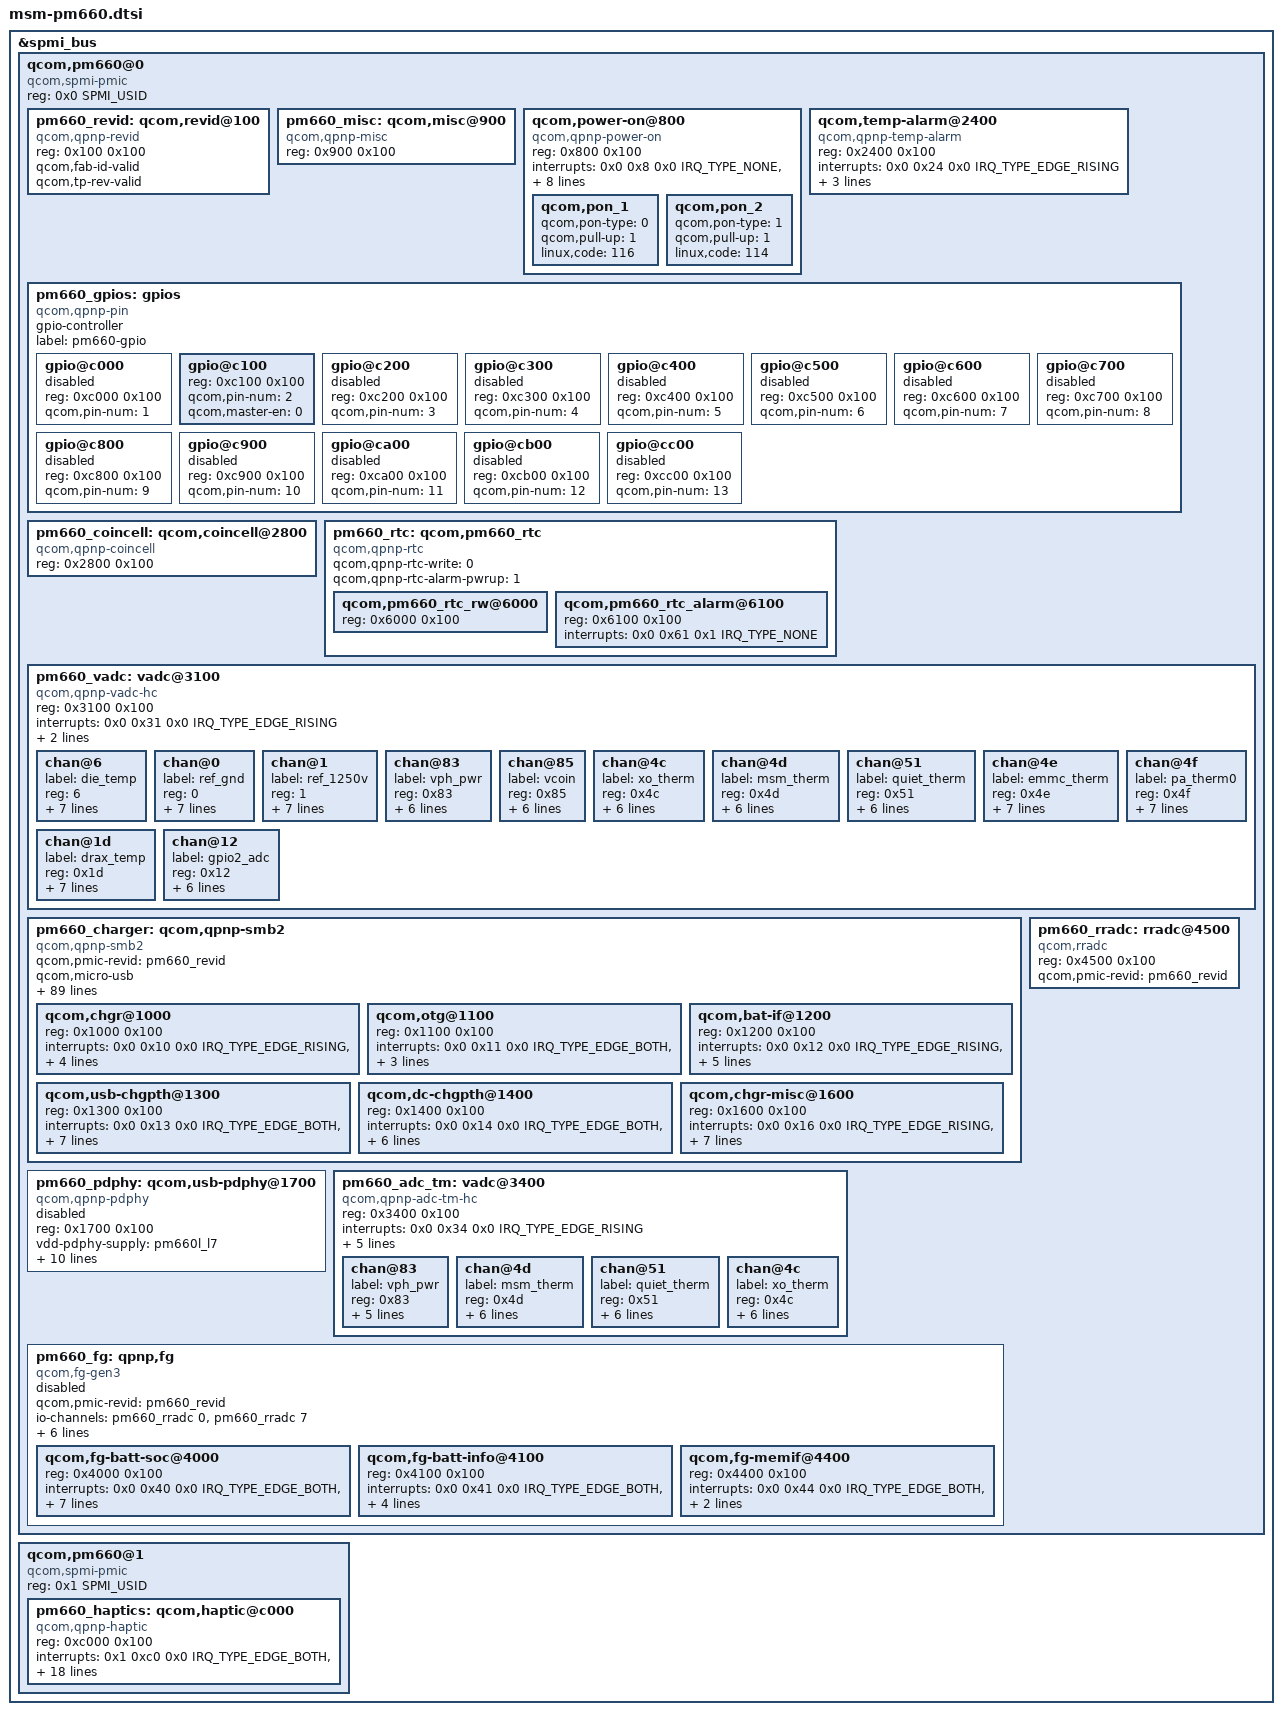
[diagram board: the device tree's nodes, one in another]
/* Copyright (c) 2016-2017, The Linux Foundation. All rights reserved.
 *
 * This program is free software; you can redistribute it and/or modify
 * it under the terms of the GNU General Public License version 2 and
 * only version 2 as published by the Free Software Foundation.
 *
 * This program is distributed in the hope that it will be useful,
 * but WITHOUT ANY WARRANTY; without even the implied warranty of
 * MERCHANTABILITY or FITNESS FOR A PARTICULAR PURPOSE.  See the
 * GNU General Public License for more details.
 */

#include <dt-bindings/spmi/spmi.h>
#include <dt-bindings/interrupt-controller/irq.h>

&spmi_bus {
	qcom,pm660@0 {
		compatible ="qcom,spmi-pmic";
		reg = <0x0 SPMI_USID>;
		#address-cells = <2>;
		#size-cells = <0>;

		pm660_revid: qcom,revid@100 {
			compatible = "qcom,qpnp-revid";
			reg = <0x100 0x100>;
			qcom,fab-id-valid;
			qcom,tp-rev-valid;
		};

		pm660_misc: qcom,misc@900 {
			compatible = "qcom,qpnp-misc";
			reg = <0x900 0x100>;
		};

		qcom,power-on@800 {
			compatible = "qcom,qpnp-power-on";
			reg = <0x800 0x100>;
			interrupts = <0x0 0x8 0x0 IRQ_TYPE_NONE>,
				     <0x0 0x8 0x1 IRQ_TYPE_NONE>,
				     <0x0 0x8 0x4 IRQ_TYPE_NONE>,
				     <0x0 0x8 0x5 IRQ_TYPE_NONE>;
			interrupt-names = "kpdpwr", "resin",
					"resin-bark", "kpdpwr-resin-bark";
			qcom,pon-dbc-delay = <15625>;
			qcom,kpdpwr-sw-debounce;
			qcom,system-reset;
			qcom,store-hard-reset-reason;
			//#ifdef VENDOR_EDIT //yixue.ge@bsp.drv add for use hard reset reason
			qcom,clear-warm-reset;
			//#endif

			qcom,pon_1 {
				qcom,pon-type = <0>;
				qcom,pull-up = <1>;
				linux,code = <116>;
			};

			qcom,pon_2 {
				qcom,pon-type = <1>;
				qcom,pull-up = <1>;
				linux,code = <114>;
			};
		};

		qcom,temp-alarm@2400 {
			compatible = "qcom,qpnp-temp-alarm";
			reg = <0x2400 0x100>;
			interrupts = <0x0 0x24 0x0 IRQ_TYPE_EDGE_RISING>;
			label = "pm660_tz";
			qcom,channel-num = <6>;
			qcom,temp_alarm-vadc = <&pm660_vadc>;
		};

		pm660_gpios: gpios {
			compatible = "qcom,qpnp-pin";
			gpio-controller;
			#gpio-cells = <2>;
			#address-cells = <1>;
			#size-cells = <1>;
			label = "pm660-gpio";

			gpio@c000 {
				reg = <0xc000 0x100>;
				qcom,pin-num = <1>;
				status = "disabled";
			};

			gpio@c100 {
				reg = <0xc100 0x100>;
				qcom,pin-num = <2>;
//#ifdef VENDOR_EDIT /* Jianchao.Shi@BSP.CHG.Basic, 2017/01/23, sjc Modify for charging */
				//status = "disabled";
				status = "ok";
				//qcom,mode = <3>; //ANA_PASS_THRU
				qcom,master-en = <0>; //disable GPIO
//#endif
			};

			gpio@c200 {
				reg = <0xc200 0x100>;
				qcom,pin-num = <3>;
				status = "disabled";
			};

			gpio@c300 {
				reg = <0xc300 0x100>;
				qcom,pin-num = <4>;
				status = "disabled";
			};

			gpio@c400 {
				reg = <0xc400 0x100>;
				qcom,pin-num = <5>;
				status = "disabled";
			};

			gpio@c500 {
				reg = <0xc500 0x100>;
				qcom,pin-num = <6>;
				status = "disabled";
			};

			gpio@c600 {
				reg = <0xc600 0x100>;
				qcom,pin-num = <7>;
				status = "disabled";
			};

			gpio@c700 {
				reg = <0xc700 0x100>;
				qcom,pin-num = <8>;
				status = "disabled";
			};

			gpio@c800 {
				reg = <0xc800 0x100>;
				qcom,pin-num = <9>;
				status = "disabled";
			};

			gpio@c900 {
				reg = <0xc900 0x100>;
				qcom,pin-num = <10>;
				status = "disabled";
			};

			gpio@ca00 {
				reg = <0xca00 0x100>;
				qcom,pin-num = <11>;
				status = "disabled";
			};

			gpio@cb00 {
				reg = <0xcb00 0x100>;
				qcom,pin-num = <12>;
				status = "disabled";
			};

			gpio@cc00 {
				reg = <0xcc00 0x100>;
				qcom,pin-num = <13>;
				status = "disabled";
			};
		};

		pm660_coincell: qcom,coincell@2800 {
			compatible = "qcom,qpnp-coincell";
			reg = <0x2800 0x100>;
		};

		pm660_rtc: qcom,pm660_rtc {
			compatible = "qcom,qpnp-rtc";
			#address-cells = <1>;
			#size-cells = <1>;
			qcom,qpnp-rtc-write = <0>;
		   //#ifndef VENDOR_EDIT
           /*Tong.han@BSP.group.TP Modified for rtc restart phone. 2014-08-12*/
           //  qcom,qpnp-rtc-alarm-pwrup = <0>;  
	       //#else
 		     qcom,qpnp-rtc-alarm-pwrup = <1>;
	       //#endif

			qcom,pm660_rtc_rw@6000 {
				reg = <0x6000 0x100>;
			};
			qcom,pm660_rtc_alarm@6100 {
				reg = <0x6100 0x100>;
				interrupts = <0x0 0x61 0x1 IRQ_TYPE_NONE>;
			};
		};

		pm660_vadc: vadc@3100 {
			compatible = "qcom,qpnp-vadc-hc";
			reg = <0x3100 0x100>;
			#address-cells = <1>;
			#size-cells = <0>;
			interrupts = <0x0 0x31 0x0 IRQ_TYPE_EDGE_RISING>;
			interrupt-names = "eoc-int-en-set";
			qcom,adc-bit-resolution = <15>;
			qcom,adc-vdd-reference = <1875>;

			chan@6 {
				label = "die_temp";
				reg = <6>;
				qcom,decimation = <2>;
				qcom,pre-div-channel-scaling = <0>;
				qcom,calibration-type = "absolute";
				qcom,scale-function = <3>;
				qcom,hw-settle-time = <0>;
				qcom,fast-avg-setup = <0>;
				qcom,cal-val = <0>;
			};

			chan@0 {
				label = "ref_gnd";
				reg = <0>;
				qcom,decimation = <2>;
				qcom,pre-div-channel-scaling = <0>;
				qcom,calibration-type = "absolute";
				qcom,scale-function = <0>;
				qcom,hw-settle-time = <0>;
				qcom,fast-avg-setup = <0>;
				qcom,cal-val = <0>;
			};

			chan@1 {
				label = "ref_1250v";
				reg = <1>;
				qcom,decimation = <2>;
				qcom,pre-div-channel-scaling = <0>;
				qcom,calibration-type = "absolute";
				qcom,scale-function = <0>;
				qcom,hw-settle-time = <0>;
				qcom,fast-avg-setup = <0>;
				qcom,cal-val = <0>;
			};

			chan@83 {
				label = "vph_pwr";
				reg = <0x83>;
				qcom,decimation = <2>;
				qcom,pre-div-channel-scaling = <1>;
				qcom,calibration-type = "absolute";
				qcom,scale-function = <0>;
				qcom,hw-settle-time = <0>;
				qcom,fast-avg-setup = <0>;
			};

			chan@85 {
				label = "vcoin";
				reg = <0x85>;
				qcom,decimation = <2>;
				qcom,pre-div-channel-scaling = <1>;
				qcom,calibration-type = "absolute";
				qcom,scale-function = <0>;
				qcom,hw-settle-time = <0>;
				qcom,fast-avg-setup = <0>;
			};

			chan@4c {
				label = "xo_therm";
				reg = <0x4c>;
				qcom,decimation = <2>;
				qcom,pre-div-channel-scaling = <0>;
				qcom,calibration-type = "ratiometric";
				qcom,scale-function = <4>;
				qcom,hw-settle-time = <2>;
				qcom,fast-avg-setup = <0>;
			};

			chan@4d {
				label = "msm_therm";
				reg = <0x4d>;
				qcom,decimation = <2>;
				qcom,pre-div-channel-scaling = <0>;
				qcom,calibration-type = "ratiometric";
				qcom,scale-function = <2>;
				qcom,hw-settle-time = <2>;
				qcom,fast-avg-setup = <0>;
			};

			chan@51 {
				label = "quiet_therm";
				reg = <0x51>;
				qcom,decimation = <2>;
				qcom,pre-div-channel-scaling = <0>;
				qcom,calibration-type = "ratiometric";
				qcom,scale-function = <2>;
				qcom,hw-settle-time = <2>;
				qcom,fast-avg-setup = <0>;
			};

			chan@4e {
				label = "emmc_therm";
				reg = <0x4e>;
				qcom,decimation = <2>;
				qcom,pre-div-channel-scaling = <0>;
				qcom,calibration-type = "ratiometric";
				qcom,scale-function = <2>;
				qcom,hw-settle-time = <2>;
				qcom,fast-avg-setup = <0>;
				qcom,vadc-thermal-node;
			};

			chan@4f {
				label = "pa_therm0";
				reg = <0x4f>;
				qcom,decimation = <2>;
				qcom,pre-div-channel-scaling = <0>;
				qcom,calibration-type = "ratiometric";
				qcom,scale-function = <2>;
				qcom,hw-settle-time = <2>;
				qcom,fast-avg-setup = <0>;
				qcom,vadc-thermal-node;
			};

			chan@1d {
				label = "drax_temp";
				reg = <0x1d>;
				qcom,decimation = <2>;
				qcom,pre-div-channel-scaling = <0>;
				qcom,calibration-type = "absolute";
				qcom,scale-function = <3>;
				qcom,hw-settle-time = <0>;
				qcom,fast-avg-setup = <0>;
				qcom,cal-val = <0>;
			};

//#ifdef VENDOR_EDIT /* Jianchao.Shi@BSP.CHG.Basic, 2017/01/23, sjc Add for charging */
			chan@12 {
				label = "gpio2_adc";
				reg = <0x12>; //channel for GPIO2
				qcom,decimation = <2>;
				qcom,pre-div-channel-scaling = <0>; //1:1 scaling
				qcom,calibration-type = "absolute";
				qcom,scale-function = <0>;
				qcom,hw-settle-time = <2>;
				qcom,fast-avg-setup = <0>;
			};
//#endif
		};

		pm660_charger: qcom,qpnp-smb2 {
			compatible = "qcom,qpnp-smb2";
			#address-cells = <1>;
			#size-cells = <1>;

			qcom,pmic-revid = <&pm660_revid>;
//#ifdef VENDOR_EDIT /* Jianchao.Shi@BSP.CHG.Basic, 2017/01/18, sjc Add for charging */
			qcom,micro-usb;
//#endif

			io-channels = <&pm660_rradc 8>,
				      <&pm660_rradc 10>,
				      <&pm660_rradc 3>,
				      <&pm660_rradc 4>;
			io-channel-names = "charger_temp",
					   "charger_temp_max",
					   "usbin_i",
					   "usbin_v";

//#ifdef VENDOR_EDIT /* Jianchao.Shi@BSP.CHG.Basic, 2017/01/20, sjc Delete for charging */
			//qcom,wipower-max-uw = <5000000>;
//#endif
			dpdm-supply = <&qusb_phy0>;
//#ifdef VENDOR_EDIT /* Jianchao.Shi@BSP.CHG.Basic, 2017/05/12, sjc Modify for BOB noise*/
			pm660l_bob-supply = <&pm660l_bob>;
//#endif

			qcom,thermal-mitigation
					= <3000000 2500000 2000000 1500000
						1000000 500000>;

//#ifdef VENDOR_EDIT /* Jianchao.Shi@BSP.CHG.Basic, 2016/12/26, sjc Add for charging */
			//for smb2:
			qcom,usb-icl-ua = <2000000>;
			qcom,fcc-max-ua = <2000000>;
			//qcom,fv-max-uv = <4373000>;
			qcom,hvdcp-disable;
			qcom,pm660chg-vadc = <&pm660_vadc>;
			//qcom,otg-cl-ua = <2000000>;

			//for oppo chg framework:
			qcom,input_current_charger_ma = <2000>;
			qcom,input_current_usb_ma = <500>;
			qcom,input_current_led_ma = <1200>;
			qcom,input_current_led_ma_forcmcc = <500>;
			qcom,input_current_camera_ma = <1200>;
			//qcom,input_current_led_ma_overtemp = <900>;
			qcom,overtemp_bat_decidegc = <350>;
			qcom,iterm-disabled = <0>;
			qcom,iterm-ma = <165>;
			qcom,recharge-mv = <100>;
			qcom,batt_capacity_mah = <3300>;

			qcom,removed_bat_decidegc = <190>;  			/*<-19C*/

			qcom,cold_bat_decidegc = <30>;  /*-3C~0C*/
			qcom,temp_cold_vfloat_mv = <3980>;
			qcom,temp_cold_fastchg_current_ma = <330>;				/* 300~364 */

			qcom,little_cold_bat_decidegc = <0>;	/*0C~5C*/
			qcom,temp_little_cold_vfloat_mv = <4373>;
			qcom,temp_little_cold_fastchg_current_ma_high = <465>;	/*0.95*0.5C 1503.5~1567.5*/
			qcom,temp_little_cold_fastchg_current_ma_low = <465>;	/*0.95*0.3C 876.5~940.5*/
			qcom,temp_little_cold_fastchg_current_ma = <465>;		/* 0.15C = 495*/

			qcom,cool_bat_decidegc = <50>;	/*5C~12C*/
			qcom,temp_cool_vfloat_mv = <4373>;
			qcom,temp_cool_fastchg_current_ma_high = <800>;			/* 0.25C = 825 */
			qcom,temp_cool_fastchg_current_ma_low = <465>;			/* 0.15C = 495 */

			qcom,little_cool_bat_decidegc = <120>;	/*12C~16C*/
			qcom,temp_little_cool_vfloat_mv = <4373>;
			qcom,temp_little_cool_fastchg_current_ma = <1450>;		/* 0.45C = 1485 */

			qcom,normal_bat_decidegc = <160>;	/*16C~45C*/
			qcom,temp_normal_fastchg_current_ma = <2000>;
			qcom,temp_normal_vfloat_mv_normalchg = <4373>;
			qcom,temp_normal_vfloat_mv_voocchg = <4373>;

			qcom,warm_bat_decidegc = <480>;		/*45C~53C*/			/* 8pin Bat Vooc project need add 3 temp */
			qcom,temp_warm_vfloat_mv = <4080>;
			qcom,temp_warm_fastchg_current_ma = <800>;				/* 0.25C = 825 */

			qcom,hot_bat_decidegc = <530>;

			qcom,non_standard_vfloat_mv = <3980>;
			qcom,non_standard_fastchg_current_ma = <512>;

			qcom,non_standard_vfloat_sw_limit = <3930>;
			qcom,cold_vfloat_sw_limit = <3930>;
			qcom,little_cold_vfloat_sw_limit = <4320>;
			qcom,cool_vfloat_sw_limit = <4320>;
			qcom,little_cool_vfloat_sw_limit = <4320>;
			qcom,normal_vfloat_sw_limit = <4320>;
			qcom,warm_vfloat_sw_limit = <4030>;
			
			qcom,short_c_bat_cv_mv = <4330>;
			qcom,short_c_bat_vfloat_mv = <3800>;
			qcom,short_c_bat_fastchg_current_ma = <512>;
			qcom,short_c_bat_vfloat_sw_limit = <3750>;
			
			qcom,max_chg_time_sec = <36000>;
			qcom,charger_hv_thr = <5800>;
			qcom,charger_lv_thr = <3400>;
			qcom,vbatt_full_thr = <4400>;
			qcom,vbatt_hv_thr = <4500>;
			qcom,vfloat_step_mv = <15>;
			qcom,non_standard_vfloat_over_sw_limit = <3990>;
			qcom,cold_vfloat_over_sw_limit = <3990>;
			qcom,little_cold_vfloat_over_sw_limit = <4395>;
			qcom,cool_vfloat_over_sw_limit = <4395>;
			qcom,little_cool_vfloat_over_sw_limit = <4395>;
			qcom,normal_vfloat_over_sw_limit = <4395>;
			qcom,warm_vfloat_over_sw_limit = <4090>;

			//for control:
			//qcom,suspend_after_full;
			qcom,check_batt_full_by_sw;
			qcom,external_gauge;
			qcom,vooc_project;
			qcom,chg_ctrl_by_lcd;
			qcom,chg_ctrl_by_camera;

			qcom,chargerid_switch-gpio = <&tlmm 65 0x00>;
			qcom,usbid-gpio = <&tlmm 49 0x00>;
			qcom,ship-gpio	= <&tlmm 113 0x00>;
			qcom,shortc-gpio = <&tlmm 60 0x00>;
			pinctrl-names = "chargerid_switch_active", "chargerid_switch_sleep", "chargerid_switch_default", "usbid_active", "usbid_sleep",
			 "ship_active", "ship_sleep", "shortc_active";
			pinctrl-0 = <&chargerid_switch_active>;
			pinctrl-1 = <&chargerid_switch_sleep>;
			pinctrl-2 = <&chargerid_switch_default>;
			pinctrl-3 = <&usbid_active>;
			pinctrl-4 = <&usbid_sleep>;
			pinctrl-5 = <&ship_active>;
			pinctrl-6 = <&ship_sleep>;
			pinctrl-7 = <&shortc_active>;
//#endif //VENDOR_EDIT

			qcom,chgr@1000 {
				reg = <0x1000 0x100>;
				interrupts =
					<0x0 0x10 0x0 IRQ_TYPE_EDGE_RISING>,
					<0x0 0x10 0x1 IRQ_TYPE_EDGE_RISING>,
					<0x0 0x10 0x2 IRQ_TYPE_EDGE_RISING>,
					<0x0 0x10 0x3 IRQ_TYPE_EDGE_RISING>,
					<0x0 0x10 0x4 IRQ_TYPE_EDGE_RISING>;

				interrupt-names = "chg-error",
						  "chg-state-change",
						  "step-chg-state-change",
						  "step-chg-soc-update-fail",
						  "step-chg-soc-update-request";
			};

			qcom,otg@1100 {
				reg = <0x1100 0x100>;
				interrupts = <0x0 0x11 0x0 IRQ_TYPE_EDGE_BOTH>,
					     <0x0 0x11 0x1 IRQ_TYPE_EDGE_BOTH>,
					     <0x0 0x11 0x2 IRQ_TYPE_EDGE_BOTH>,
					     <0x0 0x11 0x3 IRQ_TYPE_EDGE_BOTH>;

				interrupt-names = "otg-fail",
						  "otg-overcurrent",
						  "otg-oc-dis-sw-sts",
						  "testmode-change-detect";
			};

			qcom,bat-if@1200 {
				reg = <0x1200 0x100>;
				interrupts =
					<0x0 0x12 0x0 IRQ_TYPE_EDGE_RISING>,
					<0x0 0x12 0x1 IRQ_TYPE_EDGE_BOTH>,
					<0x0 0x12 0x2 IRQ_TYPE_EDGE_BOTH>,
					<0x0 0x12 0x3 IRQ_TYPE_EDGE_BOTH>,
					<0x0 0x12 0x4 IRQ_TYPE_EDGE_BOTH>,
					<0x0 0x12 0x5 IRQ_TYPE_EDGE_BOTH>;

				interrupt-names = "bat-temp",
						  "bat-ocp",
						  "bat-ov",
						  "bat-low",
						  "bat-therm-or-id-missing",
						  "bat-terminal-missing";
			};

			qcom,usb-chgpth@1300 {
				reg = <0x1300 0x100>;
				interrupts =
					<0x0 0x13 0x0 IRQ_TYPE_EDGE_BOTH>,
					<0x0 0x13 0x1 IRQ_TYPE_EDGE_BOTH>,
					<0x0 0x13 0x2 IRQ_TYPE_EDGE_BOTH>,
					<0x0 0x13 0x3 IRQ_TYPE_EDGE_BOTH>,
					<0x0 0x13 0x4 IRQ_TYPE_EDGE_BOTH>,
					<0x0 0x13 0x5 IRQ_TYPE_EDGE_RISING>,
					<0x0 0x13 0x6 IRQ_TYPE_EDGE_RISING>,
					<0x0 0x13 0x7 IRQ_TYPE_EDGE_RISING>;

				interrupt-names = "usbin-collapse",
						  "usbin-lt-3p6v",
						  "usbin-uv",
						  "usbin-ov",
						  "usbin-plugin",
						  "usbin-src-change",
						  "usbin-icl-change",
						  "type-c-change";
			};

			qcom,dc-chgpth@1400 {
				reg = <0x1400 0x100>;
				interrupts =
					<0x0 0x14 0x0 IRQ_TYPE_EDGE_BOTH>,
					<0x0 0x14 0x1 IRQ_TYPE_EDGE_BOTH>,
					<0x0 0x14 0x2 IRQ_TYPE_EDGE_BOTH>,
					<0x0 0x14 0x3 IRQ_TYPE_EDGE_BOTH>,
					<0x0 0x14 0x4 IRQ_TYPE_EDGE_BOTH>,
					<0x0 0x14 0x5 IRQ_TYPE_EDGE_BOTH>,
					<0x0 0x14 0x6 IRQ_TYPE_EDGE_RISING>;

				interrupt-names = "dcin-collapse",
						  "dcin-lt-3p6v",
						  "dcin-uv",
						  "dcin-ov",
						  "dcin-plugin",
						  "div2-en-dg",
						  "dcin-icl-change";
			};

			qcom,chgr-misc@1600 {
				reg = <0x1600 0x100>;
				interrupts =
					<0x0 0x16 0x0 IRQ_TYPE_EDGE_RISING>,
					<0x0 0x16 0x1 IRQ_TYPE_EDGE_RISING>,
					<0x0 0x16 0x2 IRQ_TYPE_EDGE_BOTH>,
					<0x0 0x16 0x3 IRQ_TYPE_EDGE_BOTH>,
					<0x0 0x16 0x4 IRQ_TYPE_EDGE_BOTH>,
					<0x0 0x16 0x5 IRQ_TYPE_EDGE_BOTH>,
					<0x0 0x16 0x6 IRQ_TYPE_EDGE_FALLING>,
					<0x0 0x16 0x7 IRQ_TYPE_EDGE_BOTH>;

				interrupt-names = "wdog-snarl",
						  "wdog-bark",
						  "aicl-fail",
						  "aicl-done",
						  "high-duty-cycle",
						  "input-current-limiting",
						  "temperature-change",
						  "switcher-power-ok";
			};
		};

		pm660_pdphy: qcom,usb-pdphy@1700 {
			compatible = "qcom,qpnp-pdphy";
			reg = <0x1700 0x100>;
			vdd-pdphy-supply = <&pm660l_l7>;
			vbus-supply = <&smb2_vbus>;
			vconn-supply = <&smb2_vconn>;
			interrupts = <0x0 0x17 0x0 IRQ_TYPE_EDGE_RISING>,
				     <0x0 0x17 0x1 IRQ_TYPE_EDGE_RISING>,
				     <0x0 0x17 0x2 IRQ_TYPE_EDGE_RISING>,
				     <0x0 0x17 0x3 IRQ_TYPE_EDGE_RISING>,
				     <0x0 0x17 0x4 IRQ_TYPE_EDGE_RISING>,
				     <0x0 0x17 0x5 IRQ_TYPE_EDGE_RISING>,
				     <0x0 0x17 0x6 IRQ_TYPE_EDGE_RISING>;

			interrupt-names = "sig-tx",
					  "sig-rx",
					  "msg-tx",
					  "msg-rx",
					  "msg-tx-failed",
					  "msg-tx-discarded",
					  "msg-rx-discarded";
//#ifdef VENDOR_EDIT /* Jianchao.Shi@BSP.CHG.Basic, 2017/01/18, sjc Add for charging */
					  status = "disabled";
//#endif
			qcom,default-sink-caps = <5000 3000>, /* 5V @ 3A */
						 <9000 3000>; /* 9V @ 3A */
		};

		pm660_adc_tm: vadc@3400 {
			compatible = "qcom,qpnp-adc-tm-hc";
			reg = <0x3400 0x100>;
			#address-cells = <1>;
			#size-cells = <0>;
			interrupts = <0x0 0x34 0x0 IRQ_TYPE_EDGE_RISING>;
			interrupt-names = "eoc-int-en-set";
			qcom,adc-bit-resolution = <15>;
			qcom,adc-vdd-reference = <1875>;
			qcom,adc_tm-vadc = <&pm660_vadc>;
			qcom,decimation = <0>;
			qcom,fast-avg-setup = <0>;

			chan@83 {
				label = "vph_pwr";
				reg = <0x83>;
				qcom,pre-div-channel-scaling = <1>;
				qcom,calibration-type = "absolute";
				qcom,scale-function = <0>;
				qcom,hw-settle-time = <0>;
				qcom,btm-channel-number = <0x60>;
			};

			chan@4d {
				label = "msm_therm";
				reg = <0x4d>;
				qcom,pre-div-channel-scaling = <0>;
				qcom,calibration-type = "ratiometric";
				qcom,scale-function = <2>;
				qcom,hw-settle-time = <2>;
				qcom,btm-channel-number = <0x68>;
				qcom,thermal-node;
			};

			chan@51 {
				label = "quiet_therm";
				reg = <0x51>;
				qcom,pre-div-channel-scaling = <0>;
				qcom,calibration-type = "ratiometric";
				qcom,scale-function = <2>;
				qcom,hw-settle-time = <2>;
				qcom,btm-channel-number = <0x70>;
				qcom,thermal-node;
			};

			chan@4c {
				label = "xo_therm";
				reg = <0x4c>;
				qcom,pre-div-channel-scaling = <0>;
				qcom,calibration-type = "ratiometric";
				qcom,scale-function = <4>;
				qcom,hw-settle-time = <2>;
				qcom,btm-channel-number = <0x78>;
				qcom,thermal-node;
			};
		};

		pm660_rradc: rradc@4500 {
			compatible = "qcom,rradc";
			reg = <0x4500 0x100>;
			#address-cells = <1>;
			#size-cells = <0>;
			#io-channel-cells = <1>;
			qcom,pmic-revid = <&pm660_revid>;
		};

		pm660_fg: qpnp,fg {
			compatible = "qcom,fg-gen3";
			#address-cells = <1>;
			#size-cells = <1>;
			qcom,pmic-revid = <&pm660_revid>;
			io-channels = <&pm660_rradc 0>,
				      <&pm660_rradc 7>;
			io-channel-names = "rradc_batt_id",
					   "rradc_die_temp";
			qcom,rradc-base = <0x4500>;
			qcom,fg-esr-timer-awake = <96 96>;
			qcom,fg-esr-timer-asleep = <256 256>;
			qcom,fg-esr-timer-charging = <0 96>;
			qcom,cycle-counter-en;
//#ifndef VENDOR_EDIT /* Jianchao.Shi@BSP.CHG.Basic, 2017/02/14, sjc Modify for charging */
			//status = "okay";
			status= "disabled";
//#endif
//#ifdef VENDOR_EDIT /* Jianchao.Shi@BSP.CHG.Basic, 2017/02/11, sjc Add for charging */
			qcom,fg-chg-term-current = <150>;
//#endif

			qcom,fg-batt-soc@4000 {
				status = "okay";
				reg = <0x4000 0x100>;
				interrupts = <0x0 0x40 0x0 IRQ_TYPE_EDGE_BOTH>,
					     <0x0 0x40 0x1 IRQ_TYPE_EDGE_BOTH>,
					     <0x0 0x40 0x2
							IRQ_TYPE_EDGE_RISING>,
					     <0x0 0x40 0x3
							IRQ_TYPE_EDGE_RISING>,
					     <0x0 0x40 0x4 IRQ_TYPE_EDGE_BOTH>,
					     <0x0 0x40 0x5
							IRQ_TYPE_EDGE_RISING>,
					     <0x0 0x40 0x6 IRQ_TYPE_EDGE_BOTH>,
					     <0x0 0x40 0x7 IRQ_TYPE_EDGE_BOTH>;
				interrupt-names = "soc-update",
						  "soc-ready",
						  "bsoc-delta",
						  "msoc-delta",
						  "msoc-low",
						  "msoc-empty",
						  "msoc-high",
						  "msoc-full";
			};

			qcom,fg-batt-info@4100 {
				status = "okay";
				reg = <0x4100 0x100>;
				interrupts = <0x0 0x41 0x0 IRQ_TYPE_EDGE_BOTH>,
					     <0x0 0x41 0x1 IRQ_TYPE_EDGE_BOTH>,
					     <0x0 0x41 0x2 IRQ_TYPE_EDGE_BOTH>,
					     <0x0 0x41 0x3 IRQ_TYPE_EDGE_BOTH>,
					     <0x0 0x41 0x6 IRQ_TYPE_EDGE_BOTH>;
				interrupt-names = "vbatt-pred-delta",
						  "vbatt-low",
						  "esr-delta",
						  "batt-missing",
						  "batt-temp-delta";
			};

			qcom,fg-memif@4400 {
				status = "okay";
				reg = <0x4400 0x100>;
				interrupts = <0x0 0x44 0x0 IRQ_TYPE_EDGE_BOTH>,
					     <0x0 0x44 0x1 IRQ_TYPE_EDGE_BOTH>,
					     <0x0 0x44 0x2 IRQ_TYPE_EDGE_BOTH>;
				interrupt-names = "ima-rdy",
						  "mem-xcp",
						  "dma-grant";
			};
		};

//#ifndef VENDOR_EDIT /* Jianchao.Shi@BSP.CHG.Basic, 2017/02/14, sjc Delete for charging */
/*
		bcl@4200 {
			compatible = "qcom,msm-bcl-lmh";
			reg = <0x4200 0xff>,
				<0x4300 0xff>;
			reg-names = "fg_user_adc",
					"fg_lmh";
			interrupts = <0x0 0x42 0x0 IRQ_TYPE_NONE>,
					<0x0 0x42 0x2 IRQ_TYPE_NONE>;
			interrupt-names = "bcl-high-ibat-int",
					"bcl-low-vbat-int";
			qcom,vbat-polling-delay-ms = <100>;
			qcom,ibat-polling-delay-ms = <100>;
		};
*/
//#endif
	};

	qcom,pm660@1 {
		compatible ="qcom,spmi-pmic";
		reg = <0x1 SPMI_USID>;
		#address-cells = <2>;
		#size-cells = <0>;

		pm660_haptics: qcom,haptic@c000 {
			compatible = "qcom,qpnp-haptic";
			reg = <0xc000 0x100>;
			interrupts = <0x1 0xc0 0x0 IRQ_TYPE_EDGE_BOTH>,
				     <0x1 0xc0 0x1 IRQ_TYPE_EDGE_BOTH>;
			interrupt-names = "sc-irq", "play-irq";
			qcom,pmic-revid = <&pm660_revid>;
			qcom,pmic-misc = <&pm660_misc>;
			qcom,misc-clk-trim-error-reg = <0xf3>;
			//#ifdef VENDOR_EDIT
			//rendong.shi@Bsp.boot.device,2016/12/21, Added for vibrator			
			qcom,actuator-type = "erm";
			//#endif
			qcom,play-mode = "direct";
			qcom,vmax-mv = <3200>;
			qcom,ilim-ma = <800>;
			qcom,wave-shape = "square";
			qcom,wave-play-rate-us = <6667>;
			qcom,int-pwm-freq-khz = <505>;
			qcom,sc-deb-cycles = <8>;
			//#ifdef VENDOR_EDIT
			//rendong.shi@Bsp.boot.device,2016/12/21, Added for vibrator
			//qcom,en-brake;
			//#endif
			qcom,brake-pattern = [03 03 00 00];
			qcom,lra-high-z = "opt0";
			qcom,lra-auto-res-mode = "qwd";
			qcom,lra-calibrate-at-eop = <0>;
			qcom,correct-lra-drive-freq;
			//#ifdef VENDOR_EDIT
			//Added by Tong.han@Bsp.group.Tp for vib min time setting,2015-07-07-07
			qcom,vib-timemin-ms = <35>;
			//#endif /*VENDOR_EDIT*
		};
	};
};
